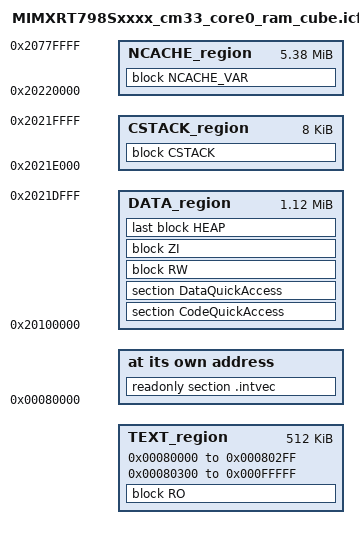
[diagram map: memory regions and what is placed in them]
/*
** ###################################################################
**     Processor:           MIMXRT798SGFOA_cm33_core0
**     Compiler:            IAR ANSI C/C++ Compiler for ARM
**     Reference manual:    iMXRT700RM Rev.1, 08/2022
**     Version:             rev. 1.0, 2022-08-01
**     Build:               b221201
**
**     Abstract:
**         Linker file for the IAR ANSI C/C++ Compiler for ARM
**
**     Copyright 2016 Freescale Semiconductor, Inc.
**     Copyright 2016-2022, 2024 NXP
**     All rights reserved.
**
**     SPDX-License-Identifier: BSD-3-Clause
**
**     http:                 www.nxp.com
**     mail:                 support@nxp.com
**
** ###################################################################
*/

/* Stack and Heap Sizes */
if (isdefinedsymbol(__stack_size__)) {
  define symbol __size_cstack__        = __stack_size__;
} else {
  define symbol __size_cstack__        = 0x2000;
}

if (isdefinedsymbol(__heap_size__)) {
  define symbol __size_heap__          = __heap_size__;
} else {
  define symbol __size_heap__          = 0x2200;
}


/* The SRAM region [0x0-0x7FFFF] is reserved for Non-cached shared memory between M33 and DSP. */


define symbol m_interrupts_start               = 0x00080000;
define symbol m_interrupts_end                 = 0x000802FF;

define symbol m_text_start                     = 0x00080300;
define symbol m_text_end                       = 0x000FFFFF;

define symbol m_data_start                     = 0x20100000;
define symbol m_data_end                       = 0x2021FFFF;

define symbol m_ncache_start                   = 0x20220000;
define symbol m_ncache_end                     = 0x2077FFFF;


/*define symbol m_boot_flash_conf_start          = 0x0007F400;*/

define exported symbol __VECTOR_TABLE          = m_interrupts_start;
define exported symbol __VECTOR_RAM            = m_interrupts_start;
define exported symbol __RAM_VECTOR_TABLE_SIZE = 0x0;

define exported symbol __NCACHE_REGION_START   = m_ncache_start;
define exported symbol __NCACHE_REGION_SIZE    = m_ncache_end - m_ncache_start + 1;

define memory mem with size = 4G;

define region TEXT_region             = mem:[from m_interrupts_start to m_interrupts_end]
                                      | mem:[from m_text_start to m_text_end];
define region DATA_region             = mem:[from m_data_start to m_data_end - __size_cstack__];
define region CSTACK_region           = mem:[from m_data_end-__size_cstack__ + 1 to m_data_end];
define region NCACHE_region           = mem:[from m_ncache_start to m_ncache_end];

define block CSTACK    with alignment = 8, size = __size_cstack__   { };
define block HEAP      with alignment = 8, size = __size_heap__     { };
define block RO        { readonly };
define block RW        { readwrite };
define block ZI        { zi };
define block NCACHE_VAR    { section NonCacheable , section NonCacheable.init };

initialize by copy { readwrite, section .textrw , section CodeQuickAccess, section DataQuickAccess };

do not initialize  { section .noinit };

keep{section .flash_conf };
/*place at address mem: m_boot_flash_conf_start    { readonly section .flash_conf };*/
place at address mem: m_interrupts_start    { readonly section .intvec };
place in TEXT_region                        { block RO };
place in DATA_region                        { section CodeQuickAccess, section DataQuickAccess };
place in DATA_region                        { block RW };
place in DATA_region                        { block ZI };
place in DATA_region                        { last block HEAP };
place in NCACHE_region                      { block NCACHE_VAR };
place in CSTACK_region                      { block CSTACK };
